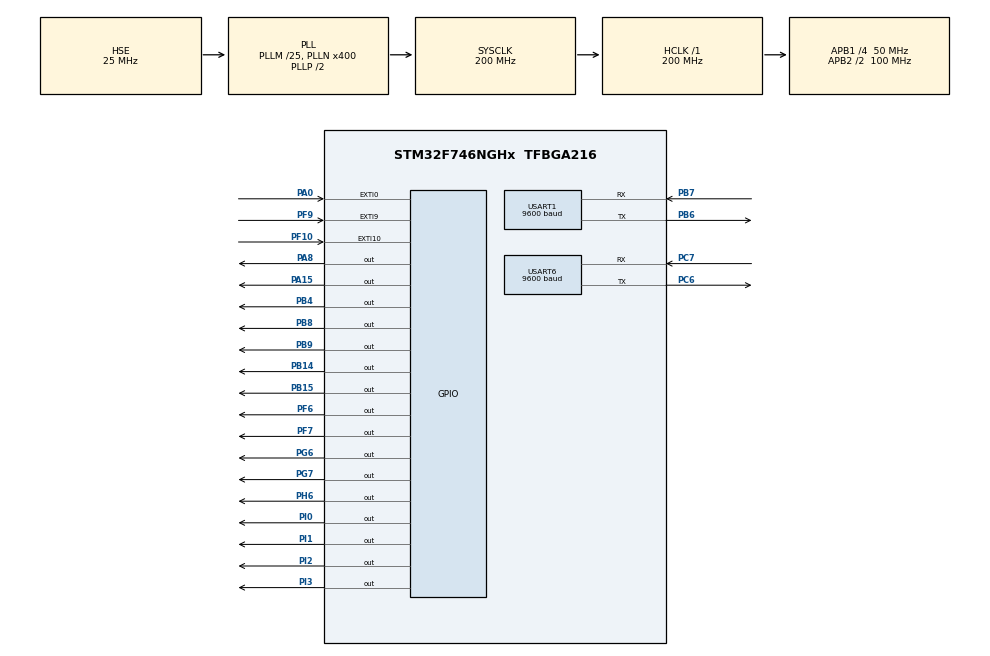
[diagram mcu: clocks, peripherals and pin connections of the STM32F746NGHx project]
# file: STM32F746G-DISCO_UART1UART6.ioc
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Mcu.Family=STM32F7
Mcu.Name=STM32F746NGHx
Mcu.Package=TFBGA216
NVIC.EXTI0_IRQn=true\:0\:0\:false\:false\:true\:true\:true
NVIC.EXTI15_10_IRQn=true\:0\:0\:false\:false\:true\:true\:true
NVIC.EXTI9_5_IRQn=true\:0\:0\:false\:false\:true\:true\:true
NVIC.PriorityGroup=NVIC_PRIORITYGROUP_4
NVIC.RCC_IRQn=true\:0\:0\:false\:false\:true\:true\:false
NVIC.TIM3_IRQn=true\:0\:0\:false\:false\:true\:true\:true
NVIC.USART1_IRQn=true\:0\:0\:false\:false\:true\:true\:true
NVIC.USART6_IRQn=true\:0\:0\:false\:false\:true\:true\:true
PA0/WKUP.GPIO_PuPd=GPIO_PULLDOWN
PA0/WKUP.Signal=GPXTI0
PA13.Mode=Serial_Wire
PA13.Signal=SYS_JTMS-SWDIO
PA14.Mode=Serial_Wire
PA14.Signal=SYS_JTCK-SWCLK
PA15.Signal=GPIO_Output
PA8.Signal=GPIO_Output
PB14.Signal=GPIO_Output
PB15.Signal=GPIO_Output
PB4.Signal=GPIO_Output
PB6.Mode=Asynchronous
PB6.Signal=USART1_TX
PB7.Mode=Asynchronous
PB7.Signal=USART1_RX
PB8.Signal=GPIO_Output
PB9.Signal=GPIO_Output
PC6.Mode=Asynchronous
PC6.Signal=USART6_TX
PC7.Mode=Asynchronous
PC7.Signal=USART6_RX
PF10.GPIO_PuPd=GPIO_PULLDOWN
PF10.Signal=GPXTI10
PF6.Signal=GPIO_Output
PF7.Signal=GPIO_Output
PF9.GPIO_PuPd=GPIO_PULLDOWN
PF9.Signal=GPXTI9
PG6.Signal=GPIO_Output
PG7.Signal=GPIO_Output
PH0/OSC_IN.Mode=HSE-External-Oscillator
PH0/OSC_IN.Signal=RCC_OSC_IN
PH1/OSC_OUT.Mode=HSE-External-Oscillator
PH1/OSC_OUT.Signal=RCC_OSC_OUT
PH6.Signal=GPIO_Output
PI0.Signal=GPIO_Output
PI1.Signal=GPIO_Output
PI2.Signal=GPIO_Output
PI3.Signal=GPIO_Output
ProjectManager.HeapSize=0x200
ProjectManager.StackSize=0x400
ProjectManager.TargetToolchain=STM32CubeIDE
RCC.AHBFreq_Value=200000000
RCC.APB1CLKDivider=RCC_HCLK_DIV4
RCC.APB1Freq_Value=50000000
RCC.APB1TimFreq_Value=100000000
RCC.APB2CLKDivider=RCC_HCLK_DIV2
RCC.APB2Freq_Value=100000000
RCC.APB2TimFreq_Value=200000000
RCC.CortexFreq_Value=200000000
RCC.HCLKFreq_Value=200000000
RCC.HSE_VALUE=25000000
RCC.HSI_VALUE=16000000
RCC.PLL48CLockSelection=RCC_CLK48SOURCE_PLLSAIP
RCC.PLLI2SN=100
RCC.PLLM=25
RCC.PLLN=400
RCC.PLLQ=9
RCC.PLLSAIN=384
RCC.PLLSAIP=RCC_PLLSAIP_DIV8
RCC.PLLSAIR=5
RCC.PLLSAIRDiv=RCC_PLLSAIDIVR_8
RCC.PLLSourceVirtual=RCC_PLLSOURCE_HSE
RCC.SDMMCClockSelection=RCC_SDMMC1CLKSOURCE_CLK48
RCC.SYSCLKFreq_VALUE=200000000
RCC.SYSCLKSource=RCC_SYSCLKSOURCE_PLLCLK
RCC.USBFreq_Value=48000000
RCC.VCOOutputFreq_Value=400000000
TIM3.Period=9999
TIM3.Prescaler=9999
USART1.BaudRate=9600
USART1.VirtualMode-Asynchronous=VM_ASYNC
USART6.BaudRate=9600
USART6.VirtualMode-Asynchronous=VM_ASYNC
VP_TIM3_VS_ClockSourceINT.Mode=Internal
board=STM32F746G-DISCO

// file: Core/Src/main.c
/* USER CODE BEGIN Header */
/**
  ******************************************************************************
  * @file           : main.c
  * @brief          : Main program body
  ******************************************************************************
  * @attention
  *
  * <h2><center>&copy; Copyright (c) 2021 STMicroelectronics.
  * All rights reserved.</center></h2>
  *
  * This software component is licensed by ST under Ultimate Liberty license
  * SLA0044, the "License"; You may not use this file except in compliance with
  * the License. You may obtain a copy of the License at:
  *                             www.st.com/SLA0044
  *
  ******************************************************************************
  */
/* USER CODE END Header */
#include "main.h"

TIM_HandleTypeDef htim3;

UART_HandleTypeDef huart1;
UART_HandleTypeDef huart6;

/* USER CODE BEGIN PV */
uint8_t rx1_data;
uint8_t rx6_data;
int inputbuff[20];
unsigned char test[4] = "test";
/* USER CODE END PV */

void SystemClock_Config(void);
static void MX_GPIO_Init(void);
static void MX_TIM3_Init(void);
static void MX_USART1_UART_Init(void);
static void MX_USART6_UART_Init(void);

/* USER CODE BEGIN 0 */
void buff_set(void){
	for(int i = 0; i < 10; i++ ){
		inputbuff[i] = 1;
	}
}

void testfuc(void) {
	for (int i = 0; i <4; i++) {
		HAL_UART_Transmit(&huart1, &test[i], 1, 10);
	}
}

/* USER CODE END 0 */

int main(void)
{

  /* MCU Configuration--------------------------------------------------------*/

  /* Reset of all peripherals, Initializes the Flash interface and the Systick. */
  HAL_Init();

  /* Configure the system clock */
  SystemClock_Config();

  /* Initialize all configured peripherals */
  MX_GPIO_Init();
  MX_TIM3_Init();
  MX_USART1_UART_Init();
  MX_USART6_UART_Init();
  /* USER CODE BEGIN 2 */
  HAL_UART_Receive_IT(&huart1, &rx1_data, 1);
  HAL_UART_Receive_IT(&huart6, &rx6_data, 1);
  buff_set();
  /* USER CODE END 2 */
  testfuc();

  /* Infinite loop */
  while (1)
  {

  }
}

void HAL_UART_RxCpltCallback(UART_HandleTypeDef *huart) {
	if (huart->Instance == USART1) {
		HAL_UART_Receive_IT(&huart1, &rx1_data, 1);

		HAL_GPIO_TogglePin(GPIOI, GPIO_PIN_1);
	}

	if (huart->Instance == USART6) {
		HAL_UART_Receive_IT(&huart6, &rx6_data, 1);
		HAL_UART_Transmit(&huart1, &rx6_data, 1, 10);

	}

}

void SystemClock_Config(void)
{
  RCC_OscInitTypeDef RCC_OscInitStruct = {0};
  RCC_ClkInitTypeDef RCC_ClkInitStruct = {0};
  RCC_PeriphCLKInitTypeDef PeriphClkInitStruct = {0};

  /** Configure the main internal regulator output voltage
  */
  __HAL_RCC_PWR_CLK_ENABLE();
  __HAL_PWR_VOLTAGESCALING_CONFIG(PWR_REGULATOR_VOLTAGE_SCALE1);
  /** Initializes the RCC Oscillators according to the specified parameters
  * in the RCC_OscInitTypeDef structure.
  */
  RCC_OscInitStruct.OscillatorType = RCC_OSCILLATORTYPE_HSE;
  RCC_OscInitStruct.HSEState = RCC_HSE_ON;
  RCC_OscInitStruct.PLL.PLLState = RCC_PLL_ON;
  RCC_OscInitStruct.PLL.PLLSource = RCC_PLLSOURCE_HSE;
  RCC_OscInitStruct.PLL.PLLM = 25;
  RCC_OscInitStruct.PLL.PLLN = 400;
  RCC_OscInitStruct.PLL.PLLP = RCC_PLLP_DIV2;
  RCC_OscInitStruct.PLL.PLLQ = 9;
  if (HAL_RCC_OscConfig(&RCC_OscInitStruct) != HAL_OK)
  {
    Error_Handler();
  }
  /** Activate the Over-Drive mode
  */
  if (HAL_PWREx_EnableOverDrive() != HAL_OK)
  {
    Error_Handler();
  }
  /** Initializes the CPU, AHB and APB buses clocks
  */
  RCC_ClkInitStruct.ClockType = RCC_CLOCKTYPE_HCLK|RCC_CLOCKTYPE_SYSCLK
                              |RCC_CLOCKTYPE_PCLK1|RCC_CLOCKTYPE_PCLK2;
  RCC_ClkInitStruct.SYSCLKSource = RCC_SYSCLKSOURCE_PLLCLK;
  RCC_ClkInitStruct.AHBCLKDivider = RCC_SYSCLK_DIV1;
  RCC_ClkInitStruct.APB1CLKDivider = RCC_HCLK_DIV4;
  RCC_ClkInitStruct.APB2CLKDivider = RCC_HCLK_DIV2;

  if (HAL_RCC_ClockConfig(&RCC_ClkInitStruct, FLASH_LATENCY_6) != HAL_OK)
  {
    Error_Handler();
  }
  PeriphClkInitStruct.PeriphClockSelection = RCC_PERIPHCLK_USART1|RCC_PERIPHCLK_USART6;
  PeriphClkInitStruct.Usart1ClockSelection = RCC_USART1CLKSOURCE_PCLK2;
  PeriphClkInitStruct.Usart6ClockSelection = RCC_USART6CLKSOURCE_PCLK2;
  if (HAL_RCCEx_PeriphCLKConfig(&PeriphClkInitStruct) != HAL_OK)
  {
    Error_Handler();
  }
}

static void MX_TIM3_Init(void)
{

  TIM_ClockConfigTypeDef sClockSourceConfig = {0};
  TIM_MasterConfigTypeDef sMasterConfig = {0};

  htim3.Instance = TIM3;
  htim3.Init.Prescaler = 9999;
  htim3.Init.CounterMode = TIM_COUNTERMODE_UP;
  htim3.Init.Period = 9999;
  htim3.Init.ClockDivision = TIM_CLOCKDIVISION_DIV1;
  htim3.Init.AutoReloadPreload = TIM_AUTORELOAD_PRELOAD_DISABLE;
  if (HAL_TIM_Base_Init(&htim3) != HAL_OK)
  {
    Error_Handler();
  }
  sClockSourceConfig.ClockSource = TIM_CLOCKSOURCE_INTERNAL;
  if (HAL_TIM_ConfigClockSource(&htim3, &sClockSourceConfig) != HAL_OK)
  {
    Error_Handler();
  }
  sMasterConfig.MasterOutputTrigger = TIM_TRGO_RESET;
  sMasterConfig.MasterSlaveMode = TIM_MASTERSLAVEMODE_DISABLE;
  if (HAL_TIMEx_MasterConfigSynchronization(&htim3, &sMasterConfig) != HAL_OK)
  {
    Error_Handler();
  }

}

static void MX_USART1_UART_Init(void)
{

  huart1.Instance = USART1;
  huart1.Init.BaudRate = 9600;
  huart1.Init.WordLength = UART_WORDLENGTH_8B;
  huart1.Init.StopBits = UART_STOPBITS_1;
  huart1.Init.Parity = UART_PARITY_NONE;
  huart1.Init.Mode = UART_MODE_TX_RX;
  huart1.Init.HwFlowCtl = UART_HWCONTROL_NONE;
  huart1.Init.OverSampling = UART_OVERSAMPLING_16;
  huart1.Init.OneBitSampling = UART_ONE_BIT_SAMPLE_DISABLE;
  huart1.AdvancedInit.AdvFeatureInit = UART_ADVFEATURE_NO_INIT;
  if (HAL_UART_Init(&huart1) != HAL_OK)
  {
    Error_Handler();
  }

}

static void MX_USART6_UART_Init(void)
{

  huart6.Instance = USART6;
  huart6.Init.BaudRate = 9600;
  huart6.Init.WordLength = UART_WORDLENGTH_8B;
  huart6.Init.StopBits = UART_STOPBITS_1;
  huart6.Init.Parity = UART_PARITY_NONE;
  huart6.Init.Mode = UART_MODE_TX_RX;
  huart6.Init.HwFlowCtl = UART_HWCONTROL_NONE;
  huart6.Init.OverSampling = UART_OVERSAMPLING_16;
  huart6.Init.OneBitSampling = UART_ONE_BIT_SAMPLE_DISABLE;
  huart6.AdvancedInit.AdvFeatureInit = UART_ADVFEATURE_NO_INIT;
  if (HAL_UART_Init(&huart6) != HAL_OK)
  {
    Error_Handler();
  }

}

static void MX_GPIO_Init(void)
{
  GPIO_InitTypeDef GPIO_InitStruct = {0};

  /* GPIO Ports Clock Enable */
  __HAL_RCC_GPIOB_CLK_ENABLE();
  __HAL_RCC_GPIOA_CLK_ENABLE();
  __HAL_RCC_GPIOI_CLK_ENABLE();
  __HAL_RCC_GPIOH_CLK_ENABLE();
  __HAL_RCC_GPIOC_CLK_ENABLE();
  __HAL_RCC_GPIOG_CLK_ENABLE();
  __HAL_RCC_GPIOF_CLK_ENABLE();

  /*Configure GPIO pin Output Level */
  HAL_GPIO_WritePin(GPIOB, GPIO_PIN_8|GPIO_PIN_4|GPIO_PIN_9|GPIO_PIN_14
                          |GPIO_PIN_15, GPIO_PIN_RESET);

  /*Configure GPIO pin Output Level */
  HAL_GPIO_WritePin(GPIOA, GPIO_PIN_15|GPIO_PIN_8, GPIO_PIN_RESET);

  /*Configure GPIO pin Output Level */
  HAL_GPIO_WritePin(GPIOI, GPIO_PIN_3|GPIO_PIN_2|GPIO_PIN_1|GPIO_PIN_0, GPIO_PIN_RESET);

  /*Configure GPIO pin Output Level */
  HAL_GPIO_WritePin(GPIOG, GPIO_PIN_7|GPIO_PIN_6, GPIO_PIN_RESET);

  /*Configure GPIO pin Output Level */
  HAL_GPIO_WritePin(GPIOF, GPIO_PIN_7|GPIO_PIN_6, GPIO_PIN_RESET);

  /*Configure GPIO pin Output Level */
  HAL_GPIO_WritePin(GPIOH, GPIO_PIN_6, GPIO_PIN_RESET);

  /*Configure GPIO pins : PB8 PB4 PB9 PB14
                           PB15 */
  GPIO_InitStruct.Pin = GPIO_PIN_8|GPIO_PIN_4|GPIO_PIN_9|GPIO_PIN_14
                          |GPIO_PIN_15;
  GPIO_InitStruct.Mode = GPIO_MODE_OUTPUT_PP;
  GPIO_InitStruct.Pull = GPIO_NOPULL;
  GPIO_InitStruct.Speed = GPIO_SPEED_FREQ_LOW;
  HAL_GPIO_Init(GPIOB, &GPIO_InitStruct);

  /*Configure GPIO pins : PA15 PA8 */
  GPIO_InitStruct.Pin = GPIO_PIN_15|GPIO_PIN_8;
  GPIO_InitStruct.Mode = GPIO_MODE_OUTPUT_PP;
  GPIO_InitStruct.Pull = GPIO_NOPULL;
  GPIO_InitStruct.Speed = GPIO_SPEED_FREQ_LOW;
  HAL_GPIO_Init(GPIOA, &GPIO_InitStruct);

  /*Configure GPIO pins : PI3 PI2 PI1 PI0 */
  GPIO_InitStruct.Pin = GPIO_PIN_3|GPIO_PIN_2|GPIO_PIN_1|GPIO_PIN_0;
  GPIO_InitStruct.Mode = GPIO_MODE_OUTPUT_PP;
  GPIO_InitStruct.Pull = GPIO_NOPULL;
  GPIO_InitStruct.Speed = GPIO_SPEED_FREQ_LOW;
  HAL_GPIO_Init(GPIOI, &GPIO_InitStruct);

  /*Configure GPIO pins : PG7 PG6 */
  GPIO_InitStruct.Pin = GPIO_PIN_7|GPIO_PIN_6;
  GPIO_InitStruct.Mode = GPIO_MODE_OUTPUT_PP;
  GPIO_InitStruct.Pull = GPIO_NOPULL;
  GPIO_InitStruct.Speed = GPIO_SPEED_FREQ_LOW;
  HAL_GPIO_Init(GPIOG, &GPIO_InitStruct);

  /*Configure GPIO pins : PF7 PF6 */
  GPIO_InitStruct.Pin = GPIO_PIN_7|GPIO_PIN_6;
  GPIO_InitStruct.Mode = GPIO_MODE_OUTPUT_PP;
  GPIO_InitStruct.Pull = GPIO_NOPULL;
  GPIO_InitStruct.Speed = GPIO_SPEED_FREQ_LOW;
  HAL_GPIO_Init(GPIOF, &GPIO_InitStruct);

  /*Configure GPIO pins : PF10 PF9 */
  GPIO_InitStruct.Pin = GPIO_PIN_10|GPIO_PIN_9;
  GPIO_InitStruct.Mode = GPIO_MODE_IT_RISING;
  GPIO_InitStruct.Pull = GPIO_PULLDOWN;
  HAL_GPIO_Init(GPIOF, &GPIO_InitStruct);

  /*Configure GPIO pin : PA0 */
  GPIO_InitStruct.Pin = GPIO_PIN_0;
  GPIO_InitStruct.Mode = GPIO_MODE_IT_RISING;
  GPIO_InitStruct.Pull = GPIO_PULLDOWN;
  HAL_GPIO_Init(GPIOA, &GPIO_InitStruct);

  /*Configure GPIO pin : PH6 */
  GPIO_InitStruct.Pin = GPIO_PIN_6;
  GPIO_InitStruct.Mode = GPIO_MODE_OUTPUT_PP;
  GPIO_InitStruct.Pull = GPIO_NOPULL;
  GPIO_InitStruct.Speed = GPIO_SPEED_FREQ_LOW;
  HAL_GPIO_Init(GPIOH, &GPIO_InitStruct);

  /* EXTI interrupt init*/
  HAL_NVIC_SetPriority(EXTI0_IRQn, 0, 0);
  HAL_NVIC_EnableIRQ(EXTI0_IRQn);

  HAL_NVIC_SetPriority(EXTI9_5_IRQn, 0, 0);
  HAL_NVIC_EnableIRQ(EXTI9_5_IRQn);

  HAL_NVIC_SetPriority(EXTI15_10_IRQn, 0, 0);
  HAL_NVIC_EnableIRQ(EXTI15_10_IRQn);

}

void Error_Handler(void)
{
  __disable_irq();
  while (1)
  {
  }
}

/************************ (C) COPYRIGHT STMicroelectronics *****END OF FILE****/
